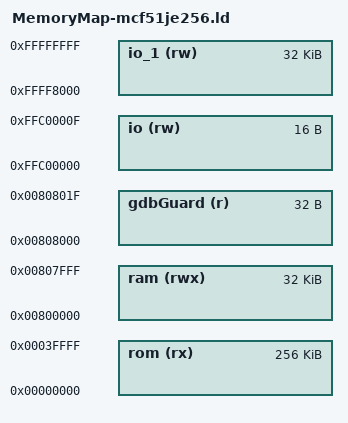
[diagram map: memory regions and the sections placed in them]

/* ---- <<< Use Configuration Wizard in Context Menu >>> ---- */

/* <o> Stack Size
   <i> Required amount of stack space  
   <0x0-0x8000> 
*/
__stack_size = 0x0100;

/* <o> GDB stack fix 
   <i> A small amount of reserve RAM used to prevent an Eclipse GDB bug that occurs when the stack is near unallocated memory
   <0-32> 
*/
__gdbstack_fix = 8;

/* <o> Minimum Heap Size 
   <i> Actual heap may be larger as it fills all unused RAM 
   <0x0-0x8000> 
*/
__heap_size  = 0x0100;

/* <h>RAM region used for stack and heap   <o0>  start <o1> length  </h> */
/* <h>Flash region used for code, data etc.<o2>  start <o3> length  </h> */
/*
 * Memory Map generated by USBDM New Project Wizard for MCF51JE256
 */
MEMORY
{
  ram            (rwx) : ORIGIN = 0x00800000, LENGTH = 0x00008000
  rom            (rx)  : ORIGIN = 0x00000000, LENGTH = 0x00040000
  io             (rw)  : ORIGIN = 0xFFC00000, LENGTH = 0x00000010
  io_1           (rw)  : ORIGIN = 0xFFFF8000, LENGTH = 0x00008000  
  
  /* Guard region above stack for GDB */
  gdbGuard       (r)   : ORIGIN = 0x00808000, LENGTH = 0x00000020
};


